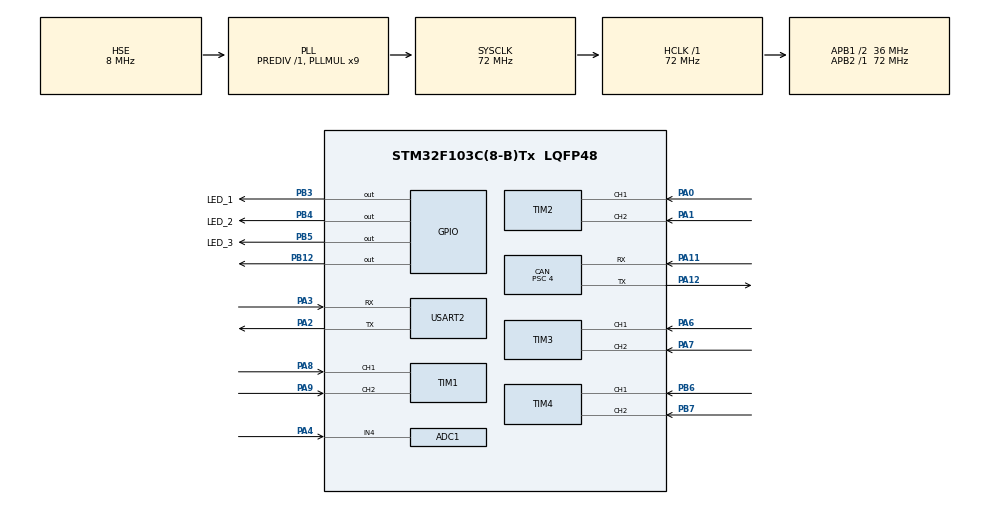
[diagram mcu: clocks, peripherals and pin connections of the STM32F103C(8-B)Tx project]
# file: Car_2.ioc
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ADC1.Channel-0\#ChannelRegularConversion=ADC_CHANNEL_4
ADC1.NbrOfConversionFlag=1
ADC1.Rank-0\#ChannelRegularConversion=1
ADC1.SamplingTime-0\#ChannelRegularConversion=ADC_SAMPLETIME_239CYCLES_5
ADC1.master=1
CAN.ABOM=DISABLE
CAN.BS1=CAN_BS1_11TQ
CAN.BS2=CAN_BS2_6TQ
CAN.CalculateBaudRate=500000
CAN.CalculateTimeBit=2000
CAN.CalculateTimeQuantum=111.11111111111111
CAN.NART=DISABLE
CAN.Prescaler=4
Mcu.Family=STM32F1
Mcu.Name=STM32F103C(8-B)Tx
Mcu.Package=LQFP48
NVIC.PriorityGroup=NVIC_PRIORITYGROUP_4
NVIC.USART2_IRQn=true\:0\:0\:false\:false\:true\:true\:true\:true
NVIC.USB_LP_CAN1_RX0_IRQn=true\:0\:0\:false\:false\:true\:true\:true\:true
PA0-WKUP.Signal=S_TIM2_CH1_ETR
PA1.Signal=S_TIM2_CH2
PA11.Mode=CAN_Activate
PA11.Signal=CAN_RX
PA12.Mode=CAN_Activate
PA12.Signal=CAN_TX
PA13.Mode=Serial_Wire
PA13.Signal=SYS_JTMS-SWDIO
PA14.Mode=Serial_Wire
PA14.Signal=SYS_JTCK-SWCLK
PA2.Mode=Asynchronous
PA2.Signal=USART2_TX
PA3.Mode=Asynchronous
PA3.Signal=USART2_RX
PA4.Signal=ADCx_IN4
PA6.Signal=S_TIM3_CH1
PA7.Signal=S_TIM3_CH2
PA8.Signal=S_TIM1_CH1
PA9.Signal=S_TIM1_CH2
PB12.PinState=GPIO_PIN_SET
PB12.Signal=GPIO_Output
PB3.GPIO_Label=LED_1
PB3.PinState=GPIO_PIN_SET
PB3.Signal=GPIO_Output
PB4.GPIO_Label=LED_2
PB4.PinState=GPIO_PIN_SET
PB4.Signal=GPIO_Output
PB5.GPIO_Label=LED_3
PB5.PinState=GPIO_PIN_SET
PB5.Signal=GPIO_Output
PB6.Signal=S_TIM4_CH1
PB7.Signal=S_TIM4_CH2
PC14-OSC32_IN.Mode=LSE-External-Oscillator
PC14-OSC32_IN.Signal=RCC_OSC32_IN
PC15-OSC32_OUT.Mode=LSE-External-Oscillator
PC15-OSC32_OUT.Signal=RCC_OSC32_OUT
PD0-OSC_IN.Mode=HSE-External-Oscillator
PD0-OSC_IN.Signal=RCC_OSC_IN
PD1-OSC_OUT.Mode=HSE-External-Oscillator
PD1-OSC_OUT.Signal=RCC_OSC_OUT
ProjectManager.HeapSize=0x200
ProjectManager.StackSize=0x400
ProjectManager.TargetToolchain=MDK-ARM V5.32
RCC.AHBFreq_Value=72000000
RCC.APB1CLKDivider=RCC_HCLK_DIV2
RCC.APB1Freq_Value=36000000
RCC.APB1TimFreq_Value=72000000
RCC.APB2Freq_Value=72000000
RCC.APB2TimFreq_Value=72000000
RCC.HCLKFreq_Value=72000000
RCC.PLLMUL=RCC_PLL_MUL9
RCC.PLLSourceVirtual=RCC_PLLSOURCE_HSE
RCC.SYSCLKFreq_VALUE=72000000
RCC.SYSCLKSource=RCC_SYSCLKSOURCE_PLLCLK
RCC.USBFreq_Value=72000000
SH.ADCx_IN4.0=ADC1_IN4,IN4
SH.S_TIM1_CH1.0=TIM1_CH1,Encoder_Interface
SH.S_TIM1_CH2.0=TIM1_CH2,Encoder_Interface
SH.S_TIM2_CH1_ETR.0=TIM2_CH1,Encoder_Interface
SH.S_TIM2_CH2.0=TIM2_CH2,Encoder_Interface
SH.S_TIM3_CH1.0=TIM3_CH1,Encoder_Interface
SH.S_TIM3_CH2.0=TIM3_CH2,Encoder_Interface
SH.S_TIM4_CH1.0=TIM4_CH1,Encoder_Interface
SH.S_TIM4_CH2.0=TIM4_CH2,Encoder_Interface
TIM1.EncoderMode=TIM_ENCODERMODE_TI12
TIM2.EncoderMode=TIM_ENCODERMODE_TI12
TIM3.EncoderMode=TIM_ENCODERMODE_TI12
TIM4.EncoderMode=TIM_ENCODERMODE_TI12
USART2.VirtualMode=VM_ASYNC
board=custom

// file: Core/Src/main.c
/* USER CODE BEGIN Header */
/**
  ******************************************************************************
  * @file           : main.c
  * @brief          : Main program body
  ******************************************************************************
  * @attention
  *
  * Copyright (c) 2026 STMicroelectronics.
  * All rights reserved.
  *
  * This software is licensed under terms that can be found in the LICENSE file
  * in the root directory of this software component.
  * If no LICENSE file comes with this software, it is provided AS-IS.
  *
  ******************************************************************************
  */
/* USER CODE END Header */
#include "main.h"
#include "adc.h"
#include "can.h"
#include "tim.h"
#include "usart.h"
#include "gpio.h"

/* USER CODE BEGIN Includes */
#include "FreeRTOS_Task.h"
/* USER CODE END Includes */

void SystemClock_Config(void);

int main(void)
{

  /* MCU Configuration--------------------------------------------------------*/

  /* Reset of all peripherals, Initializes the Flash interface and the Systick. */
  HAL_Init();

  /* Configure the system clock */
  SystemClock_Config();

  /* Initialize all configured peripherals */
  MX_GPIO_Init();
  MX_USART2_UART_Init();
  MX_TIM1_Init();
  MX_TIM2_Init();
  MX_TIM3_Init();
  MX_TIM4_Init();
  MX_CAN_Init();
  MX_ADC1_Init();
  /* USER CODE BEGIN 2 */

  //启动FreeRTOS => 后续的代码都不执行
  FreeRTOS_start();

  /* USER CODE END 2 */

  /* Infinite loop */
  while (1)
  {

  }
}

void SystemClock_Config(void)
{
  RCC_OscInitTypeDef RCC_OscInitStruct = {0};
  RCC_ClkInitTypeDef RCC_ClkInitStruct = {0};
  RCC_PeriphCLKInitTypeDef PeriphClkInit = {0};

  /** Initializes the RCC Oscillators according to the specified parameters
  * in the RCC_OscInitTypeDef structure.
  */
  RCC_OscInitStruct.OscillatorType = RCC_OSCILLATORTYPE_HSE;
  RCC_OscInitStruct.HSEState = RCC_HSE_ON;
  RCC_OscInitStruct.HSEPredivValue = RCC_HSE_PREDIV_DIV1;
  RCC_OscInitStruct.HSIState = RCC_HSI_ON;
  RCC_OscInitStruct.PLL.PLLState = RCC_PLL_ON;
  RCC_OscInitStruct.PLL.PLLSource = RCC_PLLSOURCE_HSE;
  RCC_OscInitStruct.PLL.PLLMUL = RCC_PLL_MUL9;
  if (HAL_RCC_OscConfig(&RCC_OscInitStruct) != HAL_OK)
  {
    Error_Handler();
  }

  /** Initializes the CPU, AHB and APB buses clocks
  */
  RCC_ClkInitStruct.ClockType = RCC_CLOCKTYPE_HCLK|RCC_CLOCKTYPE_SYSCLK
                              |RCC_CLOCKTYPE_PCLK1|RCC_CLOCKTYPE_PCLK2;
  RCC_ClkInitStruct.SYSCLKSource = RCC_SYSCLKSOURCE_PLLCLK;
  RCC_ClkInitStruct.AHBCLKDivider = RCC_SYSCLK_DIV1;
  RCC_ClkInitStruct.APB1CLKDivider = RCC_HCLK_DIV2;
  RCC_ClkInitStruct.APB2CLKDivider = RCC_HCLK_DIV1;

  if (HAL_RCC_ClockConfig(&RCC_ClkInitStruct, FLASH_LATENCY_2) != HAL_OK)
  {
    Error_Handler();
  }
  PeriphClkInit.PeriphClockSelection = RCC_PERIPHCLK_ADC;
  PeriphClkInit.AdcClockSelection = RCC_ADCPCLK2_DIV2;
  if (HAL_RCCEx_PeriphCLKConfig(&PeriphClkInit) != HAL_OK)
  {
    Error_Handler();
  }
}

void Error_Handler(void)
{
  __disable_irq();
  while (1)
  {
  }
}
